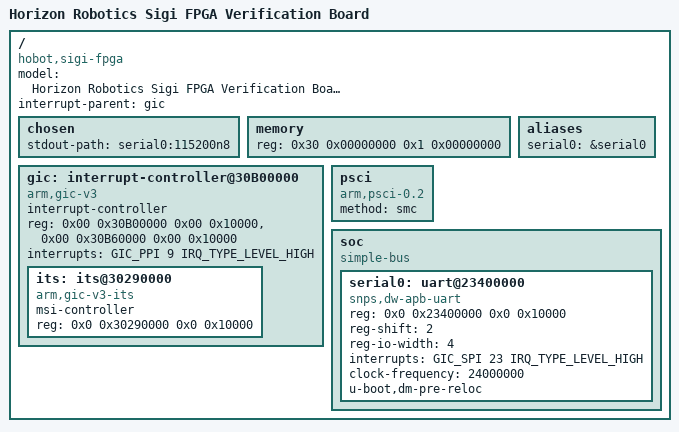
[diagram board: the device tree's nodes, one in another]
// SPDX-License-Identifier: GPL-2.0+
/*
 * Horizon Robotics Sigi Virt Platform device tree
 *
 * Copyright (C) 2023 Horizon Robotics Co,.Ltd.
 */

/dts-v1/;
#include <dt-bindings/interrupt-controller/arm-gic.h>

/ {
	model = "Horizon Robotics Sigi FPGA Verification Board";
	compatible = "hobot,sigi-fpga";
	#address-cells = <2>;
	#size-cells = <2>;
	interrupt-parent = <&gic>;

	chosen {
		stdout-path = "serial0:115200n8";
	};

	memory {
		reg = <0x30 0x00000000 0x1 0x00000000>;
		device_type = "memory";
	};

	aliases {
		serial0 = &serial0;
	};

	gic: interrupt-controller@30B00000 {
		compatible = "arm,gic-v3";
		#interrupt-cells = <3>;
		#address-cells = <2>;
		#size-cells = <2>;
		interrupt-controller;
		reg = <0x00 0x30B00000 0x00 0x10000>,
			<0x00 0x30B60000 0x00 0x10000>;
		interrupts = <GIC_PPI 9 IRQ_TYPE_LEVEL_HIGH>;
		its: its@30290000 {
			compatible = "arm,gic-v3-its";
			msi-controller;
			reg = <0x0 0x30290000 0x0 0x10000>;
		};
	};

	psci {
		compatible = "arm,psci-0.2";
		method = "smc";
	};

	soc {
		compatible = "simple-bus";
		#address-cells = <2>;
		#size-cells = <2>;
		ranges;

		serial0: uart@23400000 {
			compatible = "snps,dw-apb-uart";
			reg = <0x0 0x23400000 0x0 0x10000>;
			reg-shift = <2>;
			reg-io-width = <4>;
			interrupts = <GIC_SPI 23 IRQ_TYPE_LEVEL_HIGH>;
			clock-frequency = <24000000>; //24MHz
			u-boot,dm-pre-reloc;
			status = "okay";
		};
	};
};
